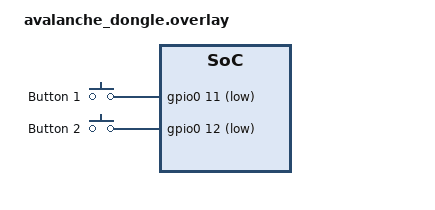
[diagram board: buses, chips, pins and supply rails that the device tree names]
/ {
    chosen {
        zmk,usb = &usb;
    };

    usb: usb {
        compatible = "zmk,usb";
        status = "okay";
    };

    gpio_keys {
        compatible = "gpio-keys";
        status = "okay";
        button@0 {
            label = "Button 1";
            gpios = <&gpio0 11 GPIO_ACTIVE_LOW>;
        };
        button@1 {
            label = "Button 2";
            gpios = <&gpio0 12 GPIO_ACTIVE_LOW>;
        };
    };
};
